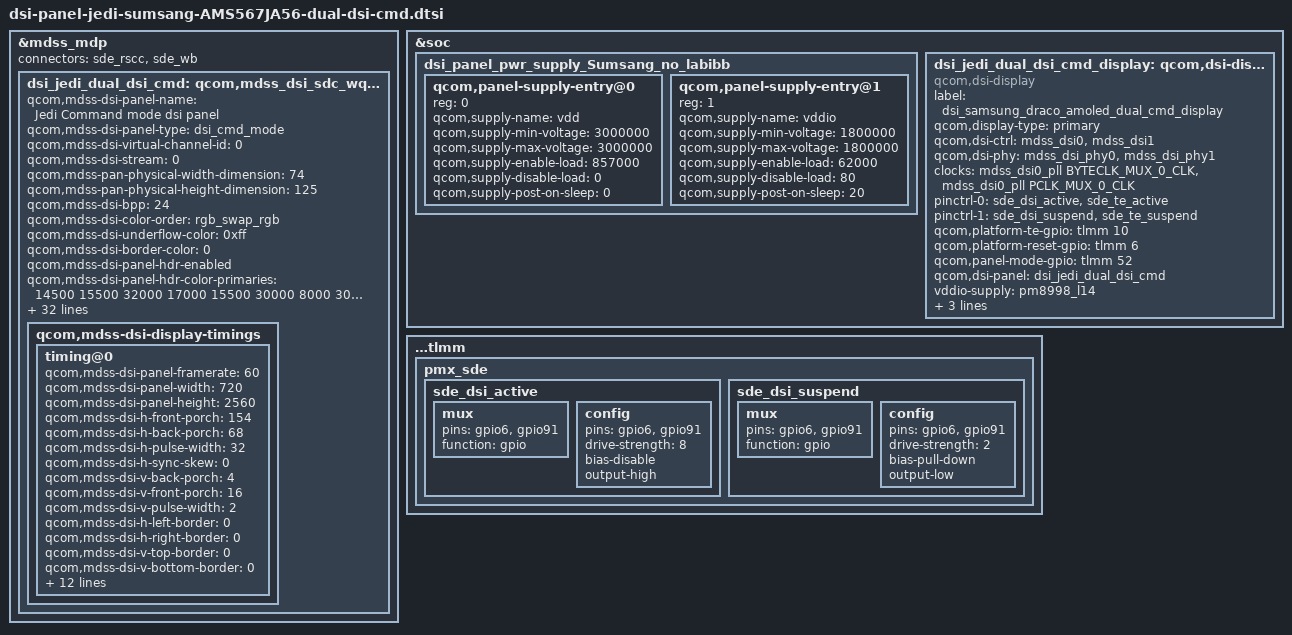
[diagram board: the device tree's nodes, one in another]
/* Copyright (c) 2017, The Linux Foundation. All rights reserved.
 *
 * This program is free software; you can redistribute it and/or modify
 * it under the terms of the GNU General Public License version 2 and
 * only version 2 as published by the Free Software Foundation.
 *
 * This program is distributed in the hope that it will be useful,
 * but WITHOUT ANY WARRANTY; without even the implied warranty of
 * MERCHANTABILITY or FITNESS FOR A PARTICULAR PURPOSE.  See the
 * GNU General Public License for more details.
 */

&mdss_mdp {
	dsi_jedi_dual_dsi_cmd: qcom,mdss_dsi_sdc_wqxga_cmd{
		qcom,mdss-dsi-panel-name =	"Jedi Command mode dsi panel";
		qcom,mdss-dsi-panel-type = "dsi_cmd_mode";
		qcom,mdss-dsi-virtual-channel-id = <0>;
		qcom,mdss-dsi-stream = <0>;
		qcom,mdss-pan-physical-width-dimension = <74>;
		qcom,mdss-pan-physical-height-dimension = <125>;
		qcom,mdss-dsi-bpp = <24>;
		qcom,mdss-dsi-color-order = "rgb_swap_rgb";   /**/
		qcom,mdss-dsi-underflow-color = <0xff>;
		qcom,mdss-dsi-border-color = <0>;
		qcom,mdss-dsi-panel-hdr-enabled;   /**/
		qcom,mdss-dsi-panel-hdr-color-primaries = <14500 15500 32000  /**/
			17000 15500 30000 8000 3000>;
		qcom,mdss-dsi-panel-peak-brightness = <4200000>;   /**/
		qcom,mdss-dsi-panel-blackness-level = <3230>;      /**/
		qcom,mdss-dsi-traffic-mode = "non_burst_sync_event";
		qcom,mdss-dsi-bllp-eof-power-mode;    /**/
		qcom,mdss-dsi-bllp-power-mode;
		qcom,mdss-dsi-lane-0-state;
		qcom,mdss-dsi-lane-1-state;
		qcom,mdss-dsi-lane-2-state;
		qcom,mdss-dsi-lane-3-state;
		qcom,adjust-timer-wakeup-ms = <1>;  /**/
		qcom,mdss-dsi-reset-sequence = <1 10>,<0 10>,<1 10>;
		qcom,mdss-dsi-dma-trigger = "trigger_sw";
		qcom,mdss-dsi-mdp-trigger = "none";
		qcom,mdss-dsi-te-pin-select = <1>;
		qcom,mdss-dsi-wr-mem-start = <0x2c>;    /**/ 
		qcom,mdss-dsi-wr-mem-continue = <0x3c>; /**/
		qcom,mdss-dsi-te-dcs-command = <1>;  /**/
		qcom,mdss-dsi-te-check-enable;
		qcom,mdss-dsi-te-using-te-pin;


		qcom,panel-supply-entries = <&dsi_panel_pwr_supply_Sumsang_no_labibb>;
		qcom,mdss-dsi-bl-pmic-control-type = "bl_ctrl_dcs";
		qcom,mdss-dsi-bl-min-level = <1>;
		qcom,mdss-dsi-bl-max-level = <255>;
		qcom,mdss-dsi-mode-sel-gpio-state = "dual_port";
		qcom,panel-mode-gpio = <&tlmm 52 0>;
		qcom,platform-reset-gpio = <&tlmm 6 0>;
		qcom,platform-te-gpio = <&tlmm 10 0>;

		qcom,mdss-dsi-t-clk-post = <0x0d>;
		qcom,mdss-dsi-t-clk-pre = <0x2b>;

		qcom,mdss-dsi-display-timings {
			timing@0{
				qcom,mdss-dsi-panel-framerate = <60>;
				qcom,mdss-dsi-panel-width = <720>;
				qcom,mdss-dsi-panel-height = <2560>;
				qcom,mdss-dsi-h-front-porch = <154>;
				qcom,mdss-dsi-h-back-porch = <68>;
				qcom,mdss-dsi-h-pulse-width = <32>;
				qcom,mdss-dsi-h-sync-skew = <0>;
				qcom,mdss-dsi-v-back-porch = <4>;
				qcom,mdss-dsi-v-front-porch = <16>;
				qcom,mdss-dsi-v-pulse-width = <2>;
				qcom,mdss-dsi-h-left-border = <0>;
				qcom,mdss-dsi-h-right-border = <0>;
				qcom,mdss-dsi-v-top-border = <0>;
				qcom,mdss-dsi-v-bottom-border = <0>;
				qcom,mdss-dsi-h-sync-pulse = <0>;
				qcom,mdss-dsi-panel-jitter = <0x1 0x1>;
				qcom,mdss-dsi-on-command = [
					05 01 00 00 00 00 02 00 00
					05 01 00 00 05 00 02 11 00
					29 01 00 00 00 00 03 F0 5A 5A
					15 01 00 00 00 00 02 C4 03
					15 01 00 00 00 00 02 F9 03
					29 01 00 00 00 00 14 C2 00 00 D8 D8 00 80 2B 05 08 0E 07 0B 05 0D 0A 15 13 20 1E
					29 01 00 00 78 00 03 F0 A5 A5
					15 01 00 00 00 00 02 35 00
					15 01 00 00 00 00 02 53 20
					05 01 00 00 00 00 02 29 00
					];
				qcom,mdss-dsi-off-command = [05 01 00 00 00 00 02 28 00
					05 01 00 00 78 00 02 10 00];
				qcom,mdss-dsi-on-command-state = "dsi_lp_mode";
				qcom,mdss-dsi-off-command-state = "dsi_hs_mode";

				qcom,mdss-dsi-panel-phy-timings = [00 1b 07 06 22 21 07
					07 04 03 04 00];
				qcom,display-topology = <2 0 2>,
							<1 0 2>;
				qcom,default-topology-index = <0>;
			};
		};

	};

};

&mdss_mdp {
	connectors = <&sde_rscc &sde_wb>;
};

#include <dt-bindings/gpio/gpio.h>
#include <dt-bindings/regulator/qcom,rpmh-regulator.h>
&soc {
	dsi_panel_pwr_supply_Sumsang_no_labibb: dsi_panel_pwr_supply_Sumsang_no_labibb {
		#address-cells = <1>;
		#size-cells = <0>;

        qcom,panel-supply-entry@0 {
			reg = <0>;
			qcom,supply-name = "vdd";
			qcom,supply-min-voltage = <3000000>;
			qcom,supply-max-voltage = <3000000>;
			qcom,supply-enable-load = <857000>;
			qcom,supply-disable-load = <0>;
			qcom,supply-post-on-sleep = <0>;
		};

		qcom,panel-supply-entry@1 {
			reg = <1>;
			qcom,supply-name = "vddio";
			qcom,supply-min-voltage = <1800000>;
			qcom,supply-max-voltage = <1800000>;
			qcom,supply-enable-load = <62000>;
			qcom,supply-disable-load = <80>;
			qcom,supply-post-on-sleep = <20>;
		};
	};

	dsi_jedi_dual_dsi_cmd_display: qcom,dsi-display@16 {
		compatible = "qcom,dsi-display";
		label = "dsi_samsung_draco_amoled_dual_cmd_display";
		qcom,display-type = "primary";

		qcom,dsi-ctrl = <&mdss_dsi0 &mdss_dsi1>;
		qcom,dsi-phy = <&mdss_dsi_phy0 &mdss_dsi_phy1>;
		clocks = <&mdss_dsi0_pll BYTECLK_MUX_0_CLK>,
			<&mdss_dsi0_pll PCLK_MUX_0_CLK>;
		clock-names = "src_byte_clk", "src_pixel_clk";

		pinctrl-names = "panel_active", "panel_suspend";
		pinctrl-0 = <&sde_dsi_active &sde_te_active>;
		pinctrl-1 = <&sde_dsi_suspend &sde_te_suspend>;
		qcom,platform-te-gpio = <&tlmm 10 0>;
		qcom,platform-reset-gpio = <&tlmm 6 0>;
		qcom,panel-mode-gpio = <&tlmm 52 0>;

		qcom,dsi-panel = <&dsi_jedi_dual_dsi_cmd>;
		vddio-supply = <&pm8998_l14>;
		vdd-supply = <&pm8998_l28>;
		lab-supply = <&lab_regulator>;
		ibb-supply = <&ibb_regulator>;
	};
};

＆tlmm{
	pmx_sde: pmx_sde {
		sde_dsi_active: sde_dsi_active {
			mux {
				pins = "gpio6", "gpio91";
				function = "gpio";
			};

			config {
				pins = "gpio6", "gpio91";
				drive-strength = <8>;   /* 8 mA */
				bias-disable;
				output-high;
			};
		};
		sde_dsi_suspend: sde_dsi_suspend {
			mux {
				pins = "gpio6", "gpio91";
				function = "gpio";
			};

			config {
				pins = "gpio6", "gpio91";
				drive-strength = <2>;   /* 2 mA */
				bias-pull-down;         /* PULL DOWN */
				output-low;
			};
		};
	};
};
